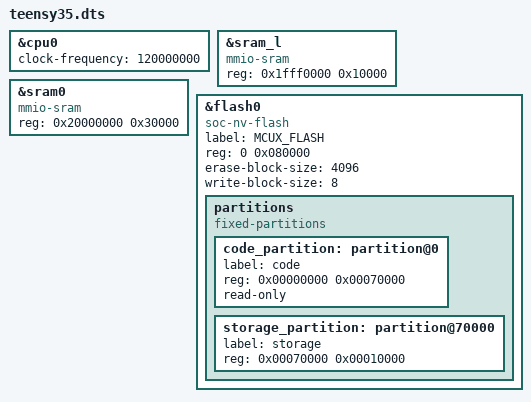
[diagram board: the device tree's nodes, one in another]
&cpu0 {
	clock-frequency = <120000000>;
};

&sram_l {
		compatible = "mmio-sram";
		reg = <0x1fff0000 0x10000>;
};

&sram0 {
		compatible = "mmio-sram";
		reg = <0x20000000 0x30000>;
};


&flash0 {
	/*
	 * For more information, see:
	 * http://docs.zephyrproject.org/latest/guides/dts/index.html#flash-partitions
	 */
	 compatible = "soc-nv-flash";
	label = "MCUX_FLASH";
	reg = <0 0x080000>;
	erase-block-size = <4096>;
	write-block-size = <8>;
	partitions {
		compatible = "fixed-partitions";
		#address-cells = <1>;
		#size-cells = <1>;

		code_partition: partition@0  {
			label = "code";
			reg = <0x00000000 0x00070000>;
			read-only;
		};

		storage_partition: partition@70000  {
			label = "storage";
			reg = <0x00070000 0x00010000>;
		};
	};
};
